# APM32F411 register map
Vendor: Geehy; File version: 2024.11.05
CPU: CM4 r1p0, little endian, 3 interrupt priority bits
Registers are 32-bit, read-write, reset 0x0 unless marked. A register's access mark holds for its fields unless they carry their own. Offsets are from the block's base; [hi:lo] are bit positions.

## SPI1 — Serial peripheral interface
Base 0x40013000
Same registers: SPI2 0x40003800, SPI3 0x40003C00, SPI4 0x40013400, SPI5 0x40015000
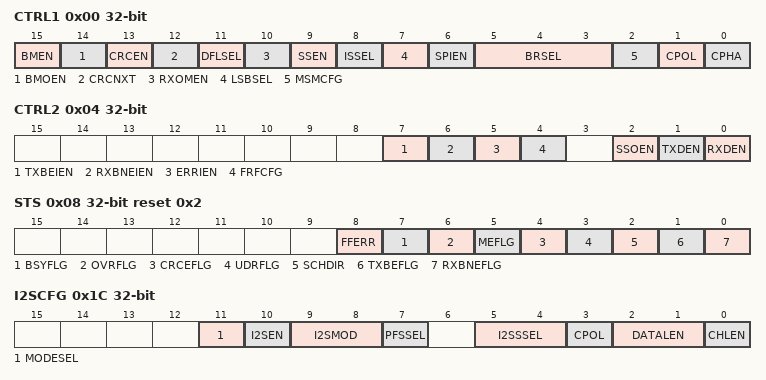
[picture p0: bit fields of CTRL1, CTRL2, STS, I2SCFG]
0x00 CTRL1 — This register is used to configure fundamental SPI parameters, including clock phase/polarity, master/slave selection, data frame format, and bidirectional mode settings. It is only used in SPI mode and not available when I2S mode is enabled.
  [15] BMEN — Enables single-line bidirectional mode (BMEN=1) or two-line unidirectional mode (BMEN=0).
    0=TWO_LINE (Two-line unidirectional mode enabled.); 1=BIDIRECTIONAL (Single-line bidirectional mode enabled.)
  [14] BMOEN — Selects output (TX-only) or input (RX-only) when in single-line bidirectional mode.
    0=INPUT (Bidirectional line is used for input only.); 1=OUTPUT (Bidirectional line is used for output only.)
  [13] CRCEN — Enables or disables the hardware-based CRC calculation for SPI in full-duplex mode.
    0=DISABLE (CRC calculation is disabled.); 1=ENABLE (CRC calculation is enabled.)
  [12] CRCNXT — Indicates whether the next transmitted data is sourced from the TX buffer or the CRC register.
    0=TX_BUFFER (Next transmitted data is taken from the TX buffer.); 1=CRC_REG (Next transmitted data is taken from the CRC register.)
  [11] DFLSEL — Selects either 8-bit or 16-bit data frame format for SPI transmissions.
    0=BIT_8 (8-bit data frame format.); 1=BIT_16 (16-bit data frame format.)
  [10] RXOMEN — Enables full-duplex (transmit/receive) or receive-only mode on the SPI lines.
    0=FULL_DUPLEX (Full-duplex transmit and receive.); 1=RECEIVE_ONLY (Receive-only mode (MOSI is unused).)
  [9] SSEN — Enables or disables software slave management (SSM) for controlling NSS.
    0=DISABLE (Software slave management disabled; external NSS is used.); 1=ENABLE (Software slave management enabled; internal NSS is used.)
  [8] ISSEL — Sets the internal NSS level when software NSS mode is enabled.
    0=NSS_LOW (Internal NSS is driven low.); 1=NSS_HIGH (Internal NSS is driven high.)
  [7] LSBSEL — Determines whether data is transmitted with MSB-first or LSB-first ordering.
    0=MSB_FIRST (MSB is transmitted first.); 1=LSB_FIRST (LSB is transmitted first.)
  [6] SPIEN — Enables or disables the SPI peripheral for communication.
    0=DISABLE (SPI peripheral is disabled.); 1=ENABLE (SPI peripheral is enabled.)
  [5:3] BRSEL — Sets the SPI clock prescaler, defining the baud rate as f_PCLK / (2^(BRSEL+1)) for these discrete options.
    0=DIV2 (f_PCLK / 2); 1=DIV4 (f_PCLK / 4); 2=DIV8 (f_PCLK / 8); 3=DIV16 (f_PCLK / 16); 4=DIV32 (f_PCLK / 32); 5=DIV64 (f_PCLK / 64); 6=DIV128 (f_PCLK / 128); 7=DIV256 (f_PCLK / 256)
  [2] MSMCFG — Selects master (MSMCFG=1) or slave (MSMCFG=0) mode operation; must be set before communication starts.
    0=SLAVE (Device operates in slave mode.); 1=MASTER (Device operates in master mode.)
  [1] CPOL — Determines the idle state of the SCK line; cannot be changed during an ongoing communication.
    0=IDLE_LOW (SCK is low level in idle state.); 1=IDLE_HIGH (SCK is high level in idle state.)
  [0] CPHA — Configures the clock phase used for data sampling; cannot be changed during an ongoing communication.
    0=FIRST_EDGE (Data is sampled on the first clock edge (odd edge).); 1=SECOND_EDGE (Data is sampled on the second clock edge (even edge).)
0x04 CTRL2 — This register provides advanced control features for the SPI peripheral, such as enabling DMA requests, configuring the SS (NSS) output, selecting the SPI frame format (Motorola or TI mode) and enabling interrupts for various SPI-related events.
  [7] TXBEIEN — Enables or disables the interrupt when the TX buffer becomes empty.
    0=DISABLE (TX buffer empty interrupt disabled.); 1=ENABLE (TX buffer empty interrupt enabled.)
  [6] RXBNEIEN — Enables or disables the interrupt when the RX buffer becomes non-empty.
    0=DISABLE (RX buffer not empty interrupt disabled.); 1=ENABLE (RX buffer not empty interrupt enabled.)
  [5] ERRIEN — Enables or disables interrupts for SPI error flags (e.g., overrun or CRC errors).
    0=DISABLE (Error interrupt disabled.); 1=ENABLE (Error interrupt enabled.)
  [4] FRFCFG — Selects SPI Motorola mode (FRFCFG=0) or SPI TI mode (FRFCFG=1).
    0=MOTOROLA (SPI Motorola frame format.); 1=TI (SPI TI frame format.)
  [2] SSOEN — Enables or disables the SS (NSS) output when operating in master mode.
    0=DISABLE (SS (NSS) output is disabled.); 1=ENABLE (SS (NSS) output is enabled in master mode.)
  [1] TXDEN — Enables or disables the DMA request when the TX buffer is empty.
    0=DISABLE (DMA request for transmit is disabled.); 1=ENABLE (DMA request for transmit is enabled.)
  [0] RXDEN — Enables or disables the DMA request when the RX buffer is not empty.
    0=DISABLE (DMA request for receive is disabled.); 1=ENABLE (DMA request for receive is enabled.)
0x08 STS access per field reset 0x2 — This register contains various status flags for SPI or I2S operation, such as buffer flags (transmit, receive), error flags (overrun, underrun, CRC error, mode fault, TI/I2S frame error), busy flag, and left/right channel indication.
  [8] FFERR ro — Indicates a frame format error in TI slave mode or a synchronization error in I2S slave mode. Cleared by reading STS.
    0=NO_ERROR (No frame format error detected); 1=ERROR (Frame format or synchronization error has been detected)
  [7] BSYFLG ro — Indicates that SPI/I2S is actively transmitting or receiving data.
    0=IDLE (No current communication); 1=BUSY (SPI/I2S is transmitting or receiving data)
  [6] OVRFLG ro — Indicates an overrun error occurred, typically when the received data is not read in time (SPI/I2S). Cleared by a read of SPI_DATA followed by a read of STS.
    0=NO_OVERRUN (No unread data was overwritten); 1=OVERRUN (Previously received data was lost due to not being read in time)
  [5] MEFLG ro — Indicates a mode fault error in SPI master mode (e.g., NSS pulled low while configured as master). SPI is forced to slave mode if set. Cleared by read/write sequence.
    0=NO_FAULT (No master mode fault detected); 1=FAULT (Master mode fault occurred)
  [4] CRCEFLG rw — Indicates that the received CRC does not match the computed CRC in SPI mode. 0 = match (no CRC error), 1 = CRC error occurred. Cleared by writing 0 to this bit. Not used in I2S mode.
    0=NOERROR (The received CRC matches the transmitted CRC); 1=ERROR (The CRC check failed)
  [3] UDRFLG ro — Indicates an underrun error has occurred (mainly in I2S slave transmit mode) if the application fails to provide data in time.
    0=NO_UNDERRUN (No underrun error occurred); 1=UNDERRUN (Data was not written in time, causing an underrun)
  [2] SCHDIR ro — Indicates whether the current data sample being transmitted or received belongs to the left or right audio channel (for I2S Philips/MSB/LSB modes). Not used in PCM standard.
    0=LEFT (Data is for the left audio channel); 1=RIGHT (Data is for the right audio channel)
  [1] TXBEFLG ro — Indicates that the transmit buffer is empty and can accept new data. In SPI/I2S mode, it is set by hardware after the data moves to the shift register.
    0=NOTEMPTY (The transmit buffer currently holds data); 1=EMPTY (The transmit buffer is empty and ready for new data)
  [0] RXBNEFLG ro — Indicates that the receive buffer contains valid data. In SPI mode, it is cleared by reading the SPI_DATA register. In I2S mode, it is cleared by reading the same data register.
    0=EMPTY (The receive buffer is empty (no new data)); 1=NOTEMPTY (The receive buffer contains valid data)
0x0C DATA
  [15:0] DATA — Writes go to the transmit buffer; reads come from the receive buffer. For an 8-bit frame, only the lower 8 bits are used. For a 16-bit frame, all 16 bits are used.
0x10 CRCPOLY reset 0x7 — This register holds the CRC (Cyclic Redundancy Check) polynomial used for hardware-based CRC computations in SPI mode. Only the lower 16 bits are valid for defining the polynomial. This register is not used in I2S mode.
  [15:0] CRCPOLY — This field specifies the polynomial for CRC computation (SPI mode only). When enabled via CRCEN, the hardware will use this polynomial to calculate and check the transmitted/received data. It is not used in I2S mode.
0x14 RXCRC ro — This register stores the hardware-calculated CRC of the data received in SPI mode. The width of this CRC matches the SPI data frame width (CRC8 if 8 bits, CRC16 if 16 bits). It is cleared by hardware when the CRCEN bit in SPI_CTRL1 is set. Not used in I2S mode. If the BSYFLG bit is set, reading this register may yield invalid data.
  [15:0] RXCRC — Holds the CRC result of the received data in SPI mode. The field width follows the configured data frame. Cleared by hardware when CRCEN is set. Not used in I2S mode.
0x18 TXCRC ro — This register stores the hardware-calculated CRC of the data transmitted in SPI mode. Its width matches the SPI data frame width (CRC8 if 8 bits, CRC16 if 16 bits). It is cleared by hardware when the CRCEN bit in SPI_CTRL1 is set. Not used in I2S mode. If the BSYFLG bit is set, reading this register may yield invalid data.
  [15:0] TXCRC — Holds the CRC result of the transmitted data in SPI mode. The field width follows the configured data frame. Cleared by hardware when CRCEN is set. Not used in I2S mode.
0x1C I2SCFG — Configures the I2S parameters. This register is used only in I2S mode (not in SPI mode). Most bits can be written only when I2SEN=0 to avoid conflicts.
  [11] MODESEL — Selects whether the peripheral works in SPI mode or I2S mode. Must be set before enabling the peripheral; not allowed to change on the fly.
    0=SPI (The peripheral operates in SPI mode.); 1=I2S (The peripheral operates in I2S mode.)
  [10] I2SEN — Enables or disables the I2S module for audio communication. This bit can be toggled at runtime to start or stop I2S. All other configuration bits must be stable before enabling I2S.
    0=DISABLE (The I2S module is disabled.); 1=ENABLE (The I2S module is enabled.)
  [9:8] I2SMOD — Selects I2S master or slave, and TX or RX (So one of these four options: Slave Transmit, Slave Receive, Master Transmit or Master Receive). Can only be changed when I2SEN=0. Not used in SPI mode.
    0=SLAVE_TX (I2S operates as slave, transmitting data.); 1=SLAVE_RX (I2S operates as slave, receiving data.); 2=MASTER_TX (I2S operates as master, transmitting data.); 3=MASTER_RX (I2S operates as master, receiving data.)
  [7] PFSSEL — Selects short- or long-frame synchronization when PCM standard (I2SSSEL=11) is used. Not used for other standards. Can only be set when I2SEN=0.
    0=SHORT (Synchronization pulse is 1 bit wide (short frame).); 1=LONG (Synchronization pulse is 13 bits wide (long frame).)
  [5:4] I2SSSEL — Selects the audio standard: I2S Philips, MSB alignment, LSB alignment, or PCM. This bit can only be configured when I2SEN=0, and is not used in SPI mode.
    0=PHILIPS (Uses the Philips I2S standard (WS toggles one bit before data).); 1=MSB_ALIGN (Uses the MSB alignment standard.); 2=LSB_ALIGN (Uses the LSB alignment standard.); 3=PCM (Uses the PCM short/long frame standard.)
  [3] CPOL — Selects the idle state (polarity) of the I2S clock line (CK). This bit can only be configured when I2SEN=0. Not used in SPI mode.
    0=IDLE_LOW (The clock line (CK) is low in idle state.); 1=IDLE_HIGH (The clock line (CK) is high in idle state.)
  [2:1] DATALEN — Selects the data length for audio samples (16/24/32 bits). If data length is extended to 32 bits, the extra bits are forced to 0 or must be handled in two 16-bit accesses. Only valid in I2S mode and can be changed only when I2S is disabled (I2SEN=0).
    0=16BIT (Audio sample size is 16 bits.); 1=24BIT (Audio sample size is 24 bits (two 16-bit accesses).); 2=32BIT (Audio sample size is 32 bits (two 16-bit accesses if using the 16-bit SPI_DATA register).); 3=DISABLE (Not used; data length is disabled.)
  [0] CHLEN — Selects the number of bits per audio channel. Must be greater than or equal to the data length. Only valid in I2S mode and can be changed only when I2S is disabled (I2SEN=0).
    0=BIT_16 (Each audio channel is 16 bits wide.); 1=BIT_32 (Each audio channel is 32 bits wide.)
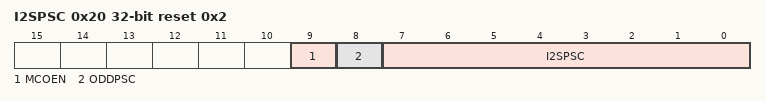
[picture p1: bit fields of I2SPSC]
0x20 I2SPSC reset 0x2 — The I2S prescaler register is used to configure the I2S clock prescaler to generate the correct audio sampling frequency. It is only valid in I2S mode (not used in SPI mode). The register must not be modified when the I2S is enabled (I2SEN=1). In particular, I2SPSC must not be set to 0 or 1.
  [9] MCOEN — Enables or disables the extra master clock output pin in I2S master mode.
    0=DISABLE (Master clock output is disabled.); 1=ENABLE (Master clock output is enabled.)
  [8] ODDPSC — Determines whether the prescaler factor is multiplied by 2 or by (2 + 1). Can only be changed when I2SEN=0.
    0=EVEN (Prescaler factor = I2SPSC * 2.); 1=ODD (Prescaler factor = (I2SPSC * 2) + 1.)
  [7:0] I2SPSC — Specifies the integer part of the I2S prescaler. Must not be 0 or 1. Can only be changed when I2SEN=0.
